# CBASS_MISC_PERI_CBASS_FW_45030000h register map
Vendor: Texas Instruments
Peripheral module from a debugger description file (folder AM275x).
Registers are 32-bit, read-write, reset 0x0 unless marked. A register's access mark holds for its fields unless they carry their own. Offsets are as the file gives them; lines under a group give offsets from that group; [hi:lo] are bit positions; {n}, {i} and the like mark numbered series; 'fields as' and 'values as' point back to an identical list; <NAME> marks a mode.

## cbass_fw (part 1 of 2)
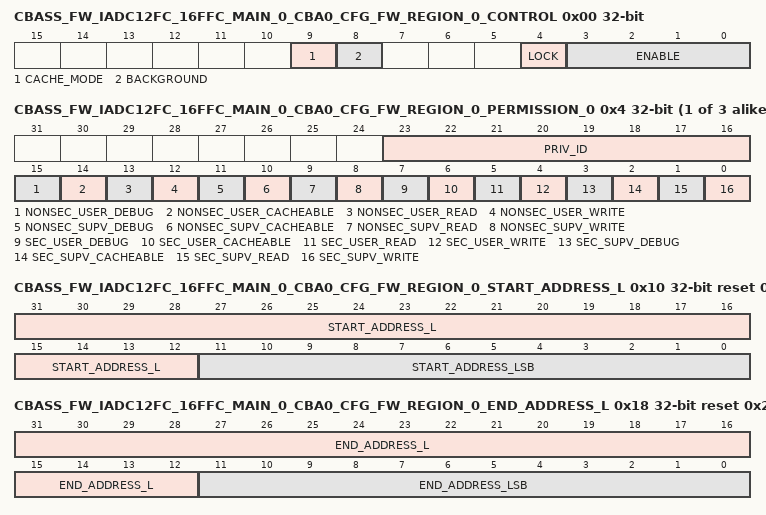
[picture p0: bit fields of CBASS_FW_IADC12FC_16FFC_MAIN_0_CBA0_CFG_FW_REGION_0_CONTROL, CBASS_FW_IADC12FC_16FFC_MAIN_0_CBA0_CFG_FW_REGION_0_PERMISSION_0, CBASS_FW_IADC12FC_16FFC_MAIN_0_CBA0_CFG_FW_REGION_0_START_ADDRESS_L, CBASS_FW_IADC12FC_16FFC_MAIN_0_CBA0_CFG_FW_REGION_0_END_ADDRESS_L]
0x00 CBASS_FW_IADC12FC_16FFC_MAIN_0_CBA0_CFG_FW_REGION_0_CONTROL access not given — The FW Region 0 Control Register defines the control fields for the target Iadc12fc_16ffc_main_0.cba0_cfg region 0 firewall.
  [9] CACHE_MODE rw — Cache mode for region. Set to 1 to check cache permissions. Set to 0 to ignore cache permissions. Reset Source: domain_default_rst_mod_g_rst_n
  [8] BACKGROUND rw — Background enable for region. There can be 1 backgroun region per FW and foreground regions can have overlapping addresses only with the background region. Reset Source: domain_default_rst_mod_g_rst_n
  [4] LOCK — Lock region. Once set region values cannot be modified. Reset Source: domain_default_rst_mod_g_rst_n (access R/W1TS)
  [3:0] ENABLE rw — Enable region. A value of 0xA enables, others disable. Reset Source: domain_default_rst_mod_g_rst_n
{0x4+4i} CBASS_FW_IADC12FC_16FFC_MAIN_0_CBA0_CFG_FW_REGION_0_PERMISSION_{i} (i=0..2) — The FW Region 0 Permission {i} Register defines the permissions for the target Iadc12fc_16ffc_main_0.cba0_cfg region 0 firewall.
  [23:16] PRIV_ID — Allowed privid. Reset Source: domain_default_rst_mod_g_rst_n
  [15] NONSEC_USER_DEBUG — Non-secure user debug allowed. Reset Source: domain_default_rst_mod_g_rst_n
  [14] NONSEC_USER_CACHEABLE — Non-secure user cacheable allowed. Reset Source: domain_default_rst_mod_g_rst_n
  [13] NONSEC_USER_READ — Non-secure user read allowed. Reset Source: domain_default_rst_mod_g_rst_n
  [12] NONSEC_USER_WRITE — Non-secure user write allowed. Reset Source: domain_default_rst_mod_g_rst_n
  [11] NONSEC_SUPV_DEBUG — Non-secure supervisor debug allowed. Reset Source: domain_default_rst_mod_g_rst_n
  [10] NONSEC_SUPV_CACHEABLE — Non-secure supervisor cacheable allowed. Reset Source: domain_default_rst_mod_g_rst_n
  [9] NONSEC_SUPV_READ — Non-secure supervisor read allowed. Reset Source: domain_default_rst_mod_g_rst_n
  [8] NONSEC_SUPV_WRITE — Non-secure supervisor write allowed. Reset Source: domain_default_rst_mod_g_rst_n
  [7] SEC_USER_DEBUG — Secure user debug allowed. Reset Source: domain_default_rst_mod_g_rst_n
  [6] SEC_USER_CACHEABLE — Secure user cacheable allowed. Reset Source: domain_default_rst_mod_g_rst_n
  [5] SEC_USER_READ — Secure user read allowed. Reset Source: domain_default_rst_mod_g_rst_n
  [4] SEC_USER_WRITE — Secure user write allowed. Reset Source: domain_default_rst_mod_g_rst_n
  [3] SEC_SUPV_DEBUG — Secure supervisor debug allowed. Reset Source: domain_default_rst_mod_g_rst_n
  [2] SEC_SUPV_CACHEABLE — Secure supervisor cacheable allowed. Reset Source: domain_default_rst_mod_g_rst_n
  [1] SEC_SUPV_READ — Secure supervisor read allowed. Reset Source: domain_default_rst_mod_g_rst_n
  [0] SEC_SUPV_WRITE — Secure supervisor write allowed. Reset Source: domain_default_rst_mod_g_rst_n
0x10 CBASS_FW_IADC12FC_16FFC_MAIN_0_CBA0_CFG_FW_REGION_0_START_ADDRESS_L access per field reset 0x20600000 — The FW Region 0 Start Address Low Register defines the start address bits 31 to 0 for the target Iadc12fc_16ffc_main_0.cba0_cfg region 0 firewall.
  [31:12] START_ADDRESS_L rw — Start address bits 31 to 12. Lowest 12 bits are forced to 0 as address must be 4KB aligned. Reset Source: domain_default_rst_mod_g_rst_n
  [11:0] START_ADDRESS_LSB ro — Start address bits 11 to 0 are forced to 0 as address must be 4KB aligned. Reset Source: domain_default_rst_mod_g_rst_n
0x14 CBASS_FW_IADC12FC_16FFC_MAIN_0_CBA0_CFG_FW_REGION_0_START_ADDRESS_H — The FW Region 0 Start Address High Register defines the start address bits 47 to 32 for the target Iadc12fc_16ffc_main_0.cba0_cfg region 0 firewall.
  [15:0] START_ADDRESS_H — Start address bits 47 to 32. Reset Source: domain_default_rst_mod_g_rst_n
0x18 CBASS_FW_IADC12FC_16FFC_MAIN_0_CBA0_CFG_FW_REGION_0_END_ADDRESS_L access per field reset 0x20600FFF — The FW Region 0 End Address Low Register defines the end address bits 31 to 0 to include for the target Iadc12fc_16ffc_main_0.cba0_cfg region 0 firewall.
  [31:12] END_ADDRESS_L rw — End address bits 31 to 12 to include in the match. Lowest 12 bits are forced to 1s as address must be 4KB aligned. Reset Source: domain_default_rst_mod_g_rst_n
  [11:0] END_ADDRESS_LSB ro — End address bits 11 to 0 are forced to 1s as address must be 4KB aligned minus 1. Reset Source: domain_default_rst_mod_g_rst_n
0x1C CBASS_FW_IADC12FC_16FFC_MAIN_0_CBA0_CFG_FW_REGION_0_END_ADDRESS_H — The FW Region 0 End Address High Register defines the end address bits 47 to 32 to include for the target Iadc12fc_16ffc_main_0.cba0_cfg region 0 firewall.
  [15:0] END_ADDRESS_H — End address bits 47 to 32 to include in the match. Reset Source: domain_default_rst_mod_g_rst_n
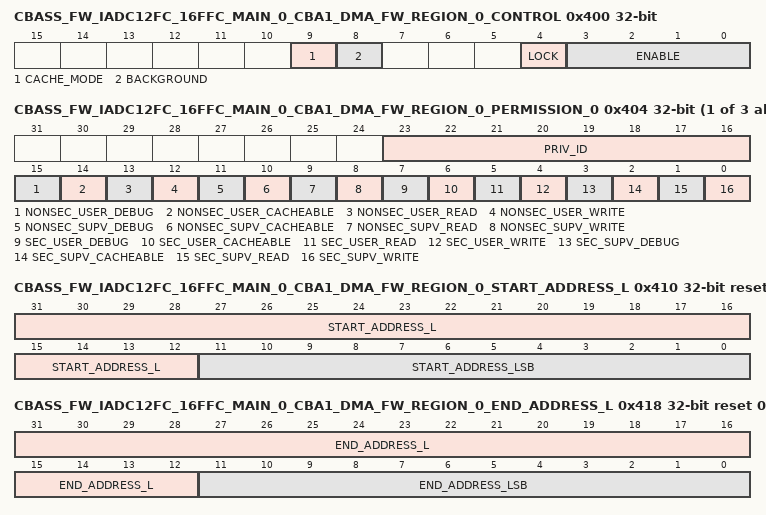
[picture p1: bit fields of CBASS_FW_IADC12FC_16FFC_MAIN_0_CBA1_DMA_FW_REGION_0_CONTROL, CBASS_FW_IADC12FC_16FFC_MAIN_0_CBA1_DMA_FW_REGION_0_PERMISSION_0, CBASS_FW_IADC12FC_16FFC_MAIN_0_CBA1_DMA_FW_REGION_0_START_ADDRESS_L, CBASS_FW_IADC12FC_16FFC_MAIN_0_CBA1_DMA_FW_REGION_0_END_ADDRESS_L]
0x400 CBASS_FW_IADC12FC_16FFC_MAIN_0_CBA1_DMA_FW_REGION_0_CONTROL access not given — The FW Region 0 Control Register defines the control fields for the target Iadc12fc_16ffc_main_0.cba1_dma region 0 firewall.
  fields as CBASS_FW_IADC12FC_16FFC_MAIN_0_CBA0_CFG_FW_REGION_0_CONTROL
{0x404+4i} CBASS_FW_IADC12FC_16FFC_MAIN_0_CBA1_DMA_FW_REGION_0_PERMISSION_{i} (i=0..2) — The FW Region 0 Permission {i} Register defines the permissions for the target Iadc12fc_16ffc_main_0.cba1_dma region 0 firewall.
  fields as CBASS_FW_IADC12FC_16FFC_MAIN_0_CBA0_CFG_FW_REGION_0_PERMISSION_0
0x410 CBASS_FW_IADC12FC_16FFC_MAIN_0_CBA1_DMA_FW_REGION_0_START_ADDRESS_L access per field reset 0x20608000 — The FW Region 0 Start Address Low Register defines the start address bits 31 to 0 for the target Iadc12fc_16ffc_main_0.cba1_dma region 0 firewall.
  fields as CBASS_FW_IADC12FC_16FFC_MAIN_0_CBA0_CFG_FW_REGION_0_START_ADDRESS_L
0x414 CBASS_FW_IADC12FC_16FFC_MAIN_0_CBA1_DMA_FW_REGION_0_START_ADDRESS_H — The FW Region 0 Start Address High Register defines the start address bits 47 to 32 for the target Iadc12fc_16ffc_main_0.cba1_dma region 0 firewall.
  fields as CBASS_FW_IADC12FC_16FFC_MAIN_0_CBA0_CFG_FW_REGION_0_START_ADDRESS_H
0x418 CBASS_FW_IADC12FC_16FFC_MAIN_0_CBA1_DMA_FW_REGION_0_END_ADDRESS_L access per field reset 0x20608FFF — The FW Region 0 End Address Low Register defines the end address bits 31 to 0 to include for the target Iadc12fc_16ffc_main_0.cba1_dma region 0 firewall.
  fields as CBASS_FW_IADC12FC_16FFC_MAIN_0_CBA0_CFG_FW_REGION_0_END_ADDRESS_L
0x41C CBASS_FW_IADC12FC_16FFC_MAIN_0_CBA1_DMA_FW_REGION_0_END_ADDRESS_H — The FW Region 0 End Address High Register defines the end address bits 47 to 32 to include for the target Iadc12fc_16ffc_main_0.cba1_dma region 0 firewall.
  fields as CBASS_FW_IADC12FC_16FFC_MAIN_0_CBA0_CFG_FW_REGION_0_END_ADDRESS_H
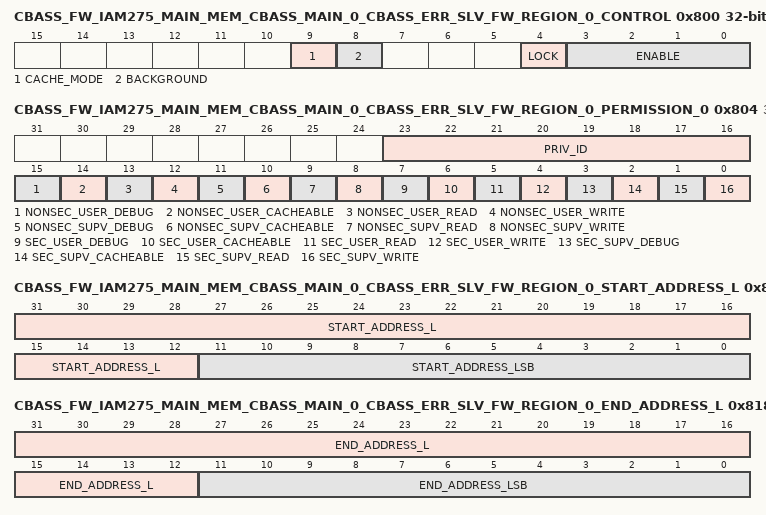
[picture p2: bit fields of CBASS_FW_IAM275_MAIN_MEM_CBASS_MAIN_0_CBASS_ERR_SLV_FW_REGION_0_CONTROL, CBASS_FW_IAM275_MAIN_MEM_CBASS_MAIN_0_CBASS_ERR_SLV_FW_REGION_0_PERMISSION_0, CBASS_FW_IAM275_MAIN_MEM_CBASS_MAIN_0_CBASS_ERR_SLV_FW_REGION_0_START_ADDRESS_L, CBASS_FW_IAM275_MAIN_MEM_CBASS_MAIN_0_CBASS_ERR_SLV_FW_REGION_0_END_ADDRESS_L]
0x800 CBASS_FW_IAM275_MAIN_MEM_CBASS_MAIN_0_CBASS_ERR_SLV_FW_REGION_0_CONTROL access not given — The FW Region 0 Control Register defines the control fields for the target Iam275_main_mem_cbass_main_0.cbass_err_slv region 0 firewall.
  fields as CBASS_FW_IADC12FC_16FFC_MAIN_0_CBA0_CFG_FW_REGION_0_CONTROL
{0x804+4i} CBASS_FW_IAM275_MAIN_MEM_CBASS_MAIN_0_CBASS_ERR_SLV_FW_REGION_0_PERMISSION_{i} (i=0..2) — The FW Region 0 Permission {i} Register defines the permissions for the target Iam275_main_mem_cbass_main_0.cbass_err_slv region 0 firewall.
  fields as CBASS_FW_IADC12FC_16FFC_MAIN_0_CBA0_CFG_FW_REGION_0_PERMISSION_0
0x810 CBASS_FW_IAM275_MAIN_MEM_CBASS_MAIN_0_CBASS_ERR_SLV_FW_REGION_0_START_ADDRESS_L access per field reset 0x20200000 — The FW Region 0 Start Address Low Register defines the start address bits 31 to 0 for the target Iam275_main_mem_cbass_main_0.cbass_err_slv region 0 firewall.
  fields as CBASS_FW_IADC12FC_16FFC_MAIN_0_CBA0_CFG_FW_REGION_0_START_ADDRESS_L
0x814 CBASS_FW_IAM275_MAIN_MEM_CBASS_MAIN_0_CBASS_ERR_SLV_FW_REGION_0_START_ADDRESS_H — The FW Region 0 Start Address High Register defines the start address bits 47 to 32 for the target Iam275_main_mem_cbass_main_0.cbass_err_slv region 0 firewall.
  fields as CBASS_FW_IADC12FC_16FFC_MAIN_0_CBA0_CFG_FW_REGION_0_START_ADDRESS_H
0x818 CBASS_FW_IAM275_MAIN_MEM_CBASS_MAIN_0_CBASS_ERR_SLV_FW_REGION_0_END_ADDRESS_L access per field reset 0x20200FFF — The FW Region 0 End Address Low Register defines the end address bits 31 to 0 to include for the target Iam275_main_mem_cbass_main_0.cbass_err_slv region 0 firewall.
  fields as CBASS_FW_IADC12FC_16FFC_MAIN_0_CBA0_CFG_FW_REGION_0_END_ADDRESS_L
0x81C CBASS_FW_IAM275_MAIN_MEM_CBASS_MAIN_0_CBASS_ERR_SLV_FW_REGION_0_END_ADDRESS_H — The FW Region 0 End Address High Register defines the end address bits 47 to 32 to include for the target Iam275_main_mem_cbass_main_0.cbass_err_slv region 0 firewall.
  fields as CBASS_FW_IADC12FC_16FFC_MAIN_0_CBA0_CFG_FW_REGION_0_END_ADDRESS_H
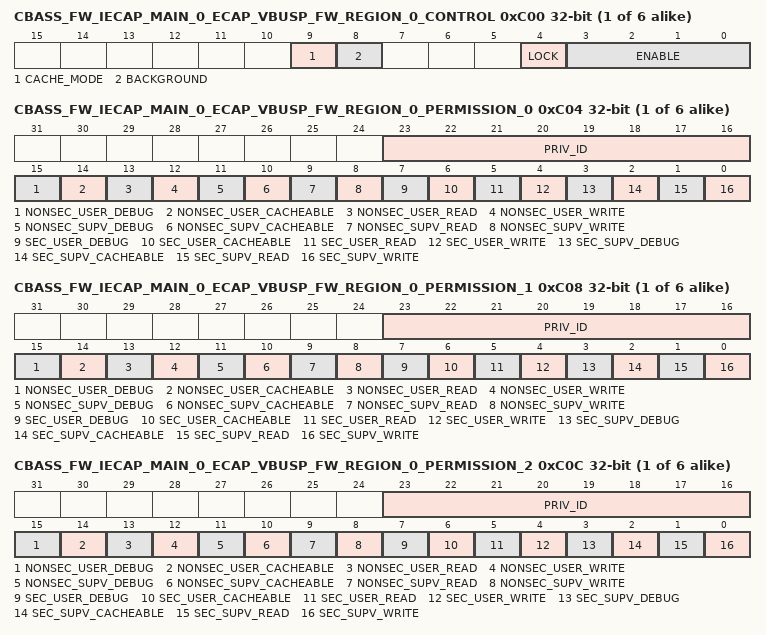
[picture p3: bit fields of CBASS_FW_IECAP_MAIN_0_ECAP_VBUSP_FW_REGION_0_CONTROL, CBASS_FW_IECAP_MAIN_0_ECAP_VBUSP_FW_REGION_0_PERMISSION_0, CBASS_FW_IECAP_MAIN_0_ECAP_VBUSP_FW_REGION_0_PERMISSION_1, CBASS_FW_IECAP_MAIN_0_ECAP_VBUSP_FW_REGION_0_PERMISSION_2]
{0xC00+0x400*i} CBASS_FW_IECAP_MAIN_{i}_ECAP_VBUSP_FW_REGION_0_CONTROL access not given (i=0..5) — The FW Region 0 Control Register defines the control fields for the target Iecap_main_{i}.ecap_vbusp region 0 firewall.
  fields as CBASS_FW_IADC12FC_16FFC_MAIN_0_CBA0_CFG_FW_REGION_0_CONTROL
{0xC04+0x400*i} CBASS_FW_IECAP_MAIN_{i}_ECAP_VBUSP_FW_REGION_0_PERMISSION_0 (i=0..5) — The FW Region 0 Permission 0 Register defines the permissions for the target Iecap_main_{i}.ecap_vbusp region 0 firewall.
  fields as CBASS_FW_IADC12FC_16FFC_MAIN_0_CBA0_CFG_FW_REGION_0_PERMISSION_0
{0xC08+0x400*i} CBASS_FW_IECAP_MAIN_{i}_ECAP_VBUSP_FW_REGION_0_PERMISSION_1 (i=0..5) — The FW Region 0 Permission 1 Register defines the permissions for the target Iecap_main_{i}.ecap_vbusp region 0 firewall.
  fields as CBASS_FW_IADC12FC_16FFC_MAIN_0_CBA0_CFG_FW_REGION_0_PERMISSION_0
{0xC0C+0x400*i} CBASS_FW_IECAP_MAIN_{i}_ECAP_VBUSP_FW_REGION_0_PERMISSION_2 (i=0..5) — The FW Region 0 Permission 2 Register defines the permissions for the target Iecap_main_{i}.ecap_vbusp region 0 firewall.
  fields as CBASS_FW_IADC12FC_16FFC_MAIN_0_CBA0_CFG_FW_REGION_0_PERMISSION_0
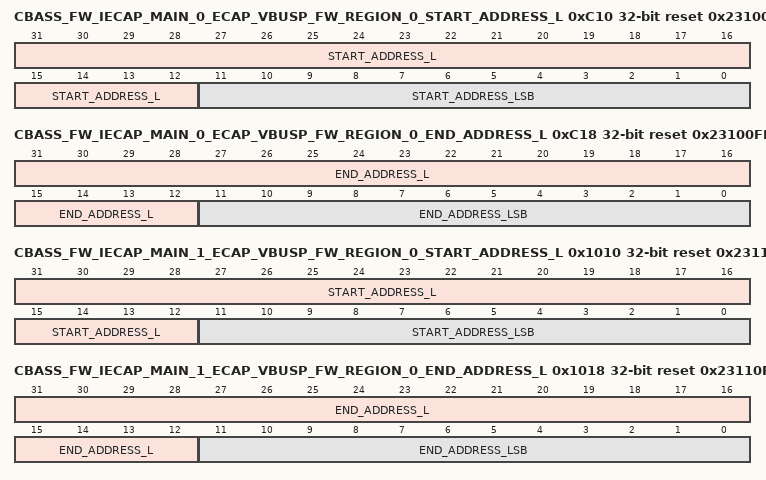
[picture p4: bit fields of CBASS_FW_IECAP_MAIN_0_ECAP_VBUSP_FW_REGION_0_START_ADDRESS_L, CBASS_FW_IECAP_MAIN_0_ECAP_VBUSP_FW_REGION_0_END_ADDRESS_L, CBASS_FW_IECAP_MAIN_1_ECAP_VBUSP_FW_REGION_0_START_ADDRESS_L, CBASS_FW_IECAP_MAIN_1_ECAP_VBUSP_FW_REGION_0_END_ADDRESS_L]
0xC10 CBASS_FW_IECAP_MAIN_0_ECAP_VBUSP_FW_REGION_0_START_ADDRESS_L access per field reset 0x23100000 — The FW Region 0 Start Address Low Register defines the start address bits 31 to 0 for the target Iecap_main_0.ecap_vbusp region 0 firewall.
  fields as CBASS_FW_IADC12FC_16FFC_MAIN_0_CBA0_CFG_FW_REGION_0_START_ADDRESS_L
{0xC14+0x400*i} CBASS_FW_IECAP_MAIN_{i}_ECAP_VBUSP_FW_REGION_0_START_ADDRESS_H (i=0..5) — The FW Region 0 Start Address High Register defines the start address bits 47 to 32 for the target Iecap_main_{i}.ecap_vbusp region 0 firewall.
  fields as CBASS_FW_IADC12FC_16FFC_MAIN_0_CBA0_CFG_FW_REGION_0_START_ADDRESS_H
0xC18 CBASS_FW_IECAP_MAIN_0_ECAP_VBUSP_FW_REGION_0_END_ADDRESS_L access per field reset 0x23100FFF — The FW Region 0 End Address Low Register defines the end address bits 31 to 0 to include for the target Iecap_main_0.ecap_vbusp region 0 firewall.
  fields as CBASS_FW_IADC12FC_16FFC_MAIN_0_CBA0_CFG_FW_REGION_0_END_ADDRESS_L
{0xC1C+0x400*i} CBASS_FW_IECAP_MAIN_{i}_ECAP_VBUSP_FW_REGION_0_END_ADDRESS_H (i=0..5) — The FW Region 0 End Address High Register defines the end address bits 47 to 32 to include for the target Iecap_main_{i}.ecap_vbusp region 0 firewall.
  fields as CBASS_FW_IADC12FC_16FFC_MAIN_0_CBA0_CFG_FW_REGION_0_END_ADDRESS_H
0x1010 CBASS_FW_IECAP_MAIN_1_ECAP_VBUSP_FW_REGION_0_START_ADDRESS_L access per field reset 0x23110000 — The FW Region 0 Start Address Low Register defines the start address bits 31 to 0 for the target Iecap_main_1.ecap_vbusp region 0 firewall.
  fields as CBASS_FW_IADC12FC_16FFC_MAIN_0_CBA0_CFG_FW_REGION_0_START_ADDRESS_L
0x1018 CBASS_FW_IECAP_MAIN_1_ECAP_VBUSP_FW_REGION_0_END_ADDRESS_L access per field reset 0x23110FFF — The FW Region 0 End Address Low Register defines the end address bits 31 to 0 to include for the target Iecap_main_1.ecap_vbusp region 0 firewall.
  fields as CBASS_FW_IADC12FC_16FFC_MAIN_0_CBA0_CFG_FW_REGION_0_END_ADDRESS_L
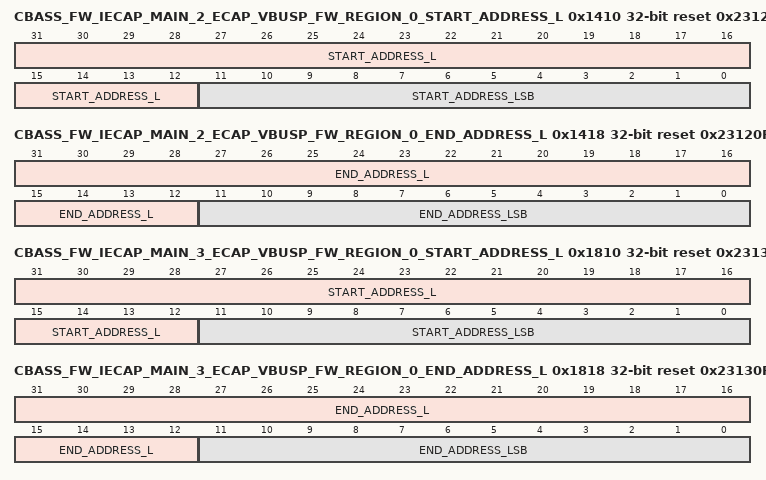
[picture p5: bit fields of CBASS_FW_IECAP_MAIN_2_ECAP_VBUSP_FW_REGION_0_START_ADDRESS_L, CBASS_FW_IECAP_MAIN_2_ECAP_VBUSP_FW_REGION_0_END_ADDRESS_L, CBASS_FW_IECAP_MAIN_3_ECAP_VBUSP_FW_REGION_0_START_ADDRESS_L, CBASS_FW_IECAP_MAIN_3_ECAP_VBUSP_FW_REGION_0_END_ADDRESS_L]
0x1410 CBASS_FW_IECAP_MAIN_2_ECAP_VBUSP_FW_REGION_0_START_ADDRESS_L access per field reset 0x23120000 — The FW Region 0 Start Address Low Register defines the start address bits 31 to 0 for the target Iecap_main_2.ecap_vbusp region 0 firewall.
  fields as CBASS_FW_IADC12FC_16FFC_MAIN_0_CBA0_CFG_FW_REGION_0_START_ADDRESS_L
0x1418 CBASS_FW_IECAP_MAIN_2_ECAP_VBUSP_FW_REGION_0_END_ADDRESS_L access per field reset 0x23120FFF — The FW Region 0 End Address Low Register defines the end address bits 31 to 0 to include for the target Iecap_main_2.ecap_vbusp region 0 firewall.
  fields as CBASS_FW_IADC12FC_16FFC_MAIN_0_CBA0_CFG_FW_REGION_0_END_ADDRESS_L
0x1810 CBASS_FW_IECAP_MAIN_3_ECAP_VBUSP_FW_REGION_0_START_ADDRESS_L access per field reset 0x23130000 — The FW Region 0 Start Address Low Register defines the start address bits 31 to 0 for the target Iecap_main_3.ecap_vbusp region 0 firewall.
  fields as CBASS_FW_IADC12FC_16FFC_MAIN_0_CBA0_CFG_FW_REGION_0_START_ADDRESS_L
0x1818 CBASS_FW_IECAP_MAIN_3_ECAP_VBUSP_FW_REGION_0_END_ADDRESS_L access per field reset 0x23130FFF — The FW Region 0 End Address Low Register defines the end address bits 31 to 0 to include for the target Iecap_main_3.ecap_vbusp region 0 firewall.
  fields as CBASS_FW_IADC12FC_16FFC_MAIN_0_CBA0_CFG_FW_REGION_0_END_ADDRESS_L
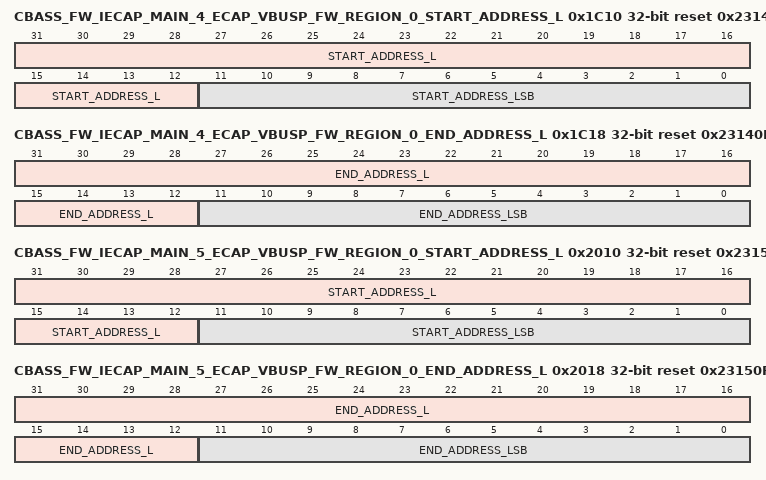
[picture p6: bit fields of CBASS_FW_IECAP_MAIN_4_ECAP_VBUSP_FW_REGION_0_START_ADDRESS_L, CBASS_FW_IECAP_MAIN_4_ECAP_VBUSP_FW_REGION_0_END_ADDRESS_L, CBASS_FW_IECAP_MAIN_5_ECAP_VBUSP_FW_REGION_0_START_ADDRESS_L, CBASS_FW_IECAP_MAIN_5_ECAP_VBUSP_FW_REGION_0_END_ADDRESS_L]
0x1C10 CBASS_FW_IECAP_MAIN_4_ECAP_VBUSP_FW_REGION_0_START_ADDRESS_L access per field reset 0x23140000 — The FW Region 0 Start Address Low Register defines the start address bits 31 to 0 for the target Iecap_main_4.ecap_vbusp region 0 firewall.
  fields as CBASS_FW_IADC12FC_16FFC_MAIN_0_CBA0_CFG_FW_REGION_0_START_ADDRESS_L
0x1C18 CBASS_FW_IECAP_MAIN_4_ECAP_VBUSP_FW_REGION_0_END_ADDRESS_L access per field reset 0x23140FFF — The FW Region 0 End Address Low Register defines the end address bits 31 to 0 to include for the target Iecap_main_4.ecap_vbusp region 0 firewall.
  fields as CBASS_FW_IADC12FC_16FFC_MAIN_0_CBA0_CFG_FW_REGION_0_END_ADDRESS_L
0x2010 CBASS_FW_IECAP_MAIN_5_ECAP_VBUSP_FW_REGION_0_START_ADDRESS_L access per field reset 0x23150000 — The FW Region 0 Start Address Low Register defines the start address bits 31 to 0 for the target Iecap_main_5.ecap_vbusp region 0 firewall.
  fields as CBASS_FW_IADC12FC_16FFC_MAIN_0_CBA0_CFG_FW_REGION_0_START_ADDRESS_L
0x2018 CBASS_FW_IECAP_MAIN_5_ECAP_VBUSP_FW_REGION_0_END_ADDRESS_L access per field reset 0x23150FFF — The FW Region 0 End Address Low Register defines the end address bits 31 to 0 to include for the target Iecap_main_5.ecap_vbusp region 0 firewall.
  fields as CBASS_FW_IADC12FC_16FFC_MAIN_0_CBA0_CFG_FW_REGION_0_END_ADDRESS_L
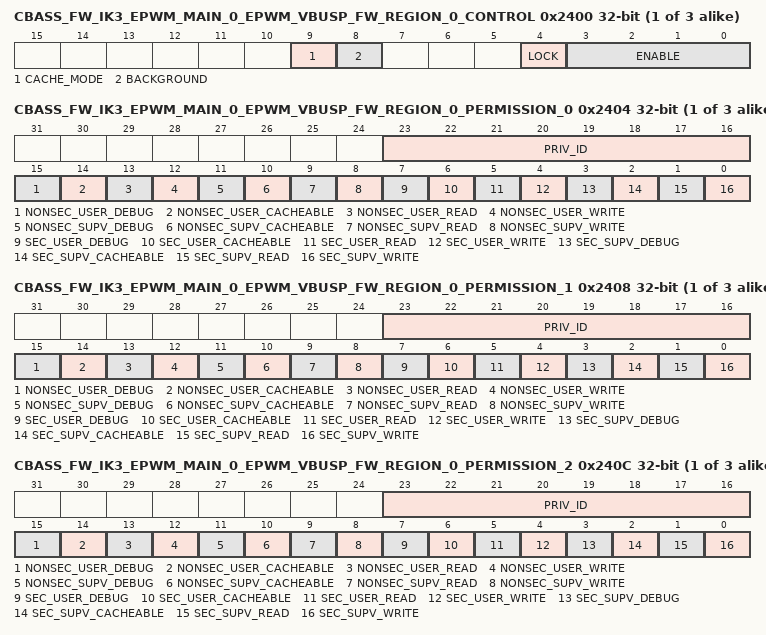
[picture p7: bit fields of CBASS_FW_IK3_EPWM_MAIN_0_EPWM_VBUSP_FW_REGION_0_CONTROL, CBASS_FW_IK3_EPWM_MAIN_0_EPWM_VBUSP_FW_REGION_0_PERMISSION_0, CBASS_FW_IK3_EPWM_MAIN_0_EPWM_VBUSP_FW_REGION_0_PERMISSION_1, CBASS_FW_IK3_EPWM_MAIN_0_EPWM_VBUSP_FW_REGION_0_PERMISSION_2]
{0x2400+0x400*i} CBASS_FW_IK3_EPWM_MAIN_{i}_EPWM_VBUSP_FW_REGION_0_CONTROL access not given (i=0..2) — The FW Region 0 Control Register defines the control fields for the target Ik3_epwm_main_{i}.epwm_vbusp region 0 firewall.
  fields as CBASS_FW_IADC12FC_16FFC_MAIN_0_CBA0_CFG_FW_REGION_0_CONTROL
{0x2404+0x400*i} CBASS_FW_IK3_EPWM_MAIN_{i}_EPWM_VBUSP_FW_REGION_0_PERMISSION_0 (i=0..2) — The FW Region 0 Permission 0 Register defines the permissions for the target Ik3_epwm_main_{i}.epwm_vbusp region 0 firewall.
  fields as CBASS_FW_IADC12FC_16FFC_MAIN_0_CBA0_CFG_FW_REGION_0_PERMISSION_0
{0x2408+0x400*i} CBASS_FW_IK3_EPWM_MAIN_{i}_EPWM_VBUSP_FW_REGION_0_PERMISSION_1 (i=0..2) — The FW Region 0 Permission 1 Register defines the permissions for the target Ik3_epwm_main_{i}.epwm_vbusp region 0 firewall.
  fields as CBASS_FW_IADC12FC_16FFC_MAIN_0_CBA0_CFG_FW_REGION_0_PERMISSION_0
{0x240C+0x400*i} CBASS_FW_IK3_EPWM_MAIN_{i}_EPWM_VBUSP_FW_REGION_0_PERMISSION_2 (i=0..2) — The FW Region 0 Permission 2 Register defines the permissions for the target Ik3_epwm_main_{i}.epwm_vbusp region 0 firewall.
  fields as CBASS_FW_IADC12FC_16FFC_MAIN_0_CBA0_CFG_FW_REGION_0_PERMISSION_0
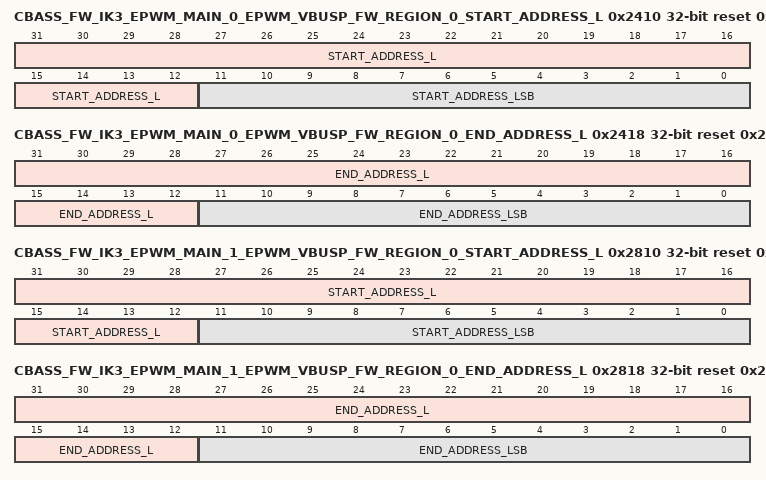
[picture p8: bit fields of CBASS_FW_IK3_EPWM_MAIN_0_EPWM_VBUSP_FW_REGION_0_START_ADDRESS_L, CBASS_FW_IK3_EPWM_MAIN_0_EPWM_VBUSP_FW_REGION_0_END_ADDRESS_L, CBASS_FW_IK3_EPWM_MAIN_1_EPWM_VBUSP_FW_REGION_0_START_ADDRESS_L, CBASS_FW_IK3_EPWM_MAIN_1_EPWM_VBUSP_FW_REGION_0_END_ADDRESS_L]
0x2410 CBASS_FW_IK3_EPWM_MAIN_0_EPWM_VBUSP_FW_REGION_0_START_ADDRESS_L access per field reset 0x23000000 — The FW Region 0 Start Address Low Register defines the start address bits 31 to 0 for the target Ik3_epwm_main_0.epwm_vbusp region 0 firewall.
  fields as CBASS_FW_IADC12FC_16FFC_MAIN_0_CBA0_CFG_FW_REGION_0_START_ADDRESS_L
{0x2414+0x400*i} CBASS_FW_IK3_EPWM_MAIN_{i}_EPWM_VBUSP_FW_REGION_0_START_ADDRESS_H (i=0..2) — The FW Region 0 Start Address High Register defines the start address bits 47 to 32 for the target Ik3_epwm_main_{i}.epwm_vbusp region 0 firewall.
  fields as CBASS_FW_IADC12FC_16FFC_MAIN_0_CBA0_CFG_FW_REGION_0_START_ADDRESS_H
0x2418 CBASS_FW_IK3_EPWM_MAIN_0_EPWM_VBUSP_FW_REGION_0_END_ADDRESS_L access per field reset 0x23000FFF — The FW Region 0 End Address Low Register defines the end address bits 31 to 0 to include for the target Ik3_epwm_main_0.epwm_vbusp region 0 firewall.
  fields as CBASS_FW_IADC12FC_16FFC_MAIN_0_CBA0_CFG_FW_REGION_0_END_ADDRESS_L
{0x241C+0x400*i} CBASS_FW_IK3_EPWM_MAIN_{i}_EPWM_VBUSP_FW_REGION_0_END_ADDRESS_H (i=0..2) — The FW Region 0 End Address High Register defines the end address bits 47 to 32 to include for the target Ik3_epwm_main_{i}.epwm_vbusp region 0 firewall.
  fields as CBASS_FW_IADC12FC_16FFC_MAIN_0_CBA0_CFG_FW_REGION_0_END_ADDRESS_H
0x2810 CBASS_FW_IK3_EPWM_MAIN_1_EPWM_VBUSP_FW_REGION_0_START_ADDRESS_L access per field reset 0x23010000 — The FW Region 0 Start Address Low Register defines the start address bits 31 to 0 for the target Ik3_epwm_main_1.epwm_vbusp region 0 firewall.
  fields as CBASS_FW_IADC12FC_16FFC_MAIN_0_CBA0_CFG_FW_REGION_0_START_ADDRESS_L
0x2818 CBASS_FW_IK3_EPWM_MAIN_1_EPWM_VBUSP_FW_REGION_0_END_ADDRESS_L access per field reset 0x23010FFF — The FW Region 0 End Address Low Register defines the end address bits 31 to 0 to include for the target Ik3_epwm_main_1.epwm_vbusp region 0 firewall.
  fields as CBASS_FW_IADC12FC_16FFC_MAIN_0_CBA0_CFG_FW_REGION_0_END_ADDRESS_L
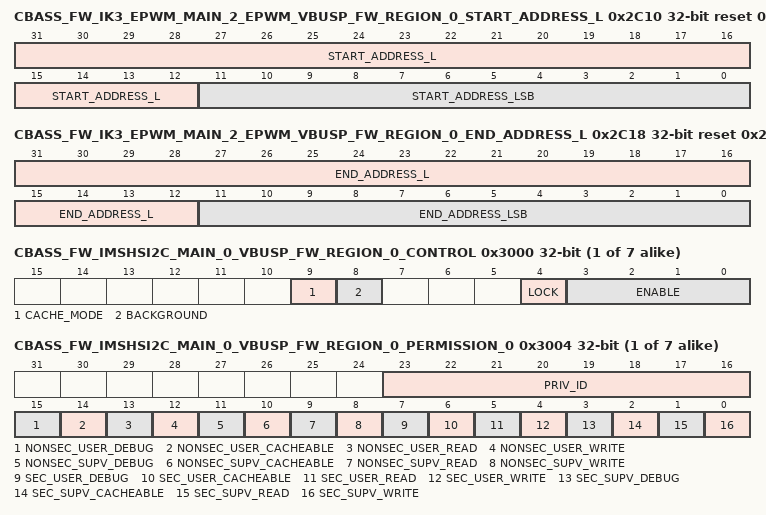
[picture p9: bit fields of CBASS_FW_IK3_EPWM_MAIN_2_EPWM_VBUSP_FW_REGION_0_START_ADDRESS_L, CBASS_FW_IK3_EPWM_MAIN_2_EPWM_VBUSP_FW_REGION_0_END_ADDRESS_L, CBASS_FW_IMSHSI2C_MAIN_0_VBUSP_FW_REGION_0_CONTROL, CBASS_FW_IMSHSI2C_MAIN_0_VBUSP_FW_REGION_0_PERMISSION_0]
0x2C10 CBASS_FW_IK3_EPWM_MAIN_2_EPWM_VBUSP_FW_REGION_0_START_ADDRESS_L access per field reset 0x23020000 — The FW Region 0 Start Address Low Register defines the start address bits 31 to 0 for the target Ik3_epwm_main_2.epwm_vbusp region 0 firewall.
  fields as CBASS_FW_IADC12FC_16FFC_MAIN_0_CBA0_CFG_FW_REGION_0_START_ADDRESS_L
0x2C18 CBASS_FW_IK3_EPWM_MAIN_2_EPWM_VBUSP_FW_REGION_0_END_ADDRESS_L access per field reset 0x23020FFF — The FW Region 0 End Address Low Register defines the end address bits 31 to 0 to include for the target Ik3_epwm_main_2.epwm_vbusp region 0 firewall.
  fields as CBASS_FW_IADC12FC_16FFC_MAIN_0_CBA0_CFG_FW_REGION_0_END_ADDRESS_L
{0x3000+0x400*i} CBASS_FW_IMSHSI2C_MAIN_{i}_VBUSP_FW_REGION_0_CONTROL access not given (i=0..6) — The FW Region 0 Control Register defines the control fields for the target Imshsi2c_main_{i}.vbusp region 0 firewall.
  fields as CBASS_FW_IADC12FC_16FFC_MAIN_0_CBA0_CFG_FW_REGION_0_CONTROL
{0x3004+0x400*i} CBASS_FW_IMSHSI2C_MAIN_{i}_VBUSP_FW_REGION_0_PERMISSION_0 (i=0..6) — The FW Region 0 Permission 0 Register defines the permissions for the target Imshsi2c_main_{i}.vbusp region 0 firewall.
  fields as CBASS_FW_IADC12FC_16FFC_MAIN_0_CBA0_CFG_FW_REGION_0_PERMISSION_0
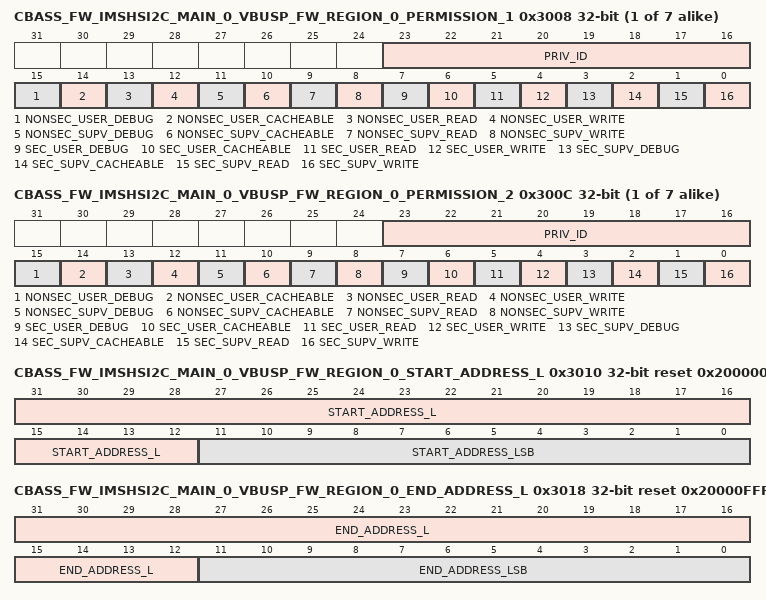
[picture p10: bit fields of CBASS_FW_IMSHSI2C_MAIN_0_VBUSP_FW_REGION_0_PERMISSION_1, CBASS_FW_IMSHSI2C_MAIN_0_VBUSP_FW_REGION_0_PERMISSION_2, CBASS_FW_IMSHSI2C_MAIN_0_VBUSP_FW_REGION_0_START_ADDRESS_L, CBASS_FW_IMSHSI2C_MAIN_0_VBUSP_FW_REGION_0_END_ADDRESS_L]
{0x3008+0x400*i} CBASS_FW_IMSHSI2C_MAIN_{i}_VBUSP_FW_REGION_0_PERMISSION_1 (i=0..6) — The FW Region 0 Permission 1 Register defines the permissions for the target Imshsi2c_main_{i}.vbusp region 0 firewall.
  fields as CBASS_FW_IADC12FC_16FFC_MAIN_0_CBA0_CFG_FW_REGION_0_PERMISSION_0
{0x300C+0x400*i} CBASS_FW_IMSHSI2C_MAIN_{i}_VBUSP_FW_REGION_0_PERMISSION_2 (i=0..6) — The FW Region 0 Permission 2 Register defines the permissions for the target Imshsi2c_main_{i}.vbusp region 0 firewall.
  fields as CBASS_FW_IADC12FC_16FFC_MAIN_0_CBA0_CFG_FW_REGION_0_PERMISSION_0
0x3010 CBASS_FW_IMSHSI2C_MAIN_0_VBUSP_FW_REGION_0_START_ADDRESS_L access per field reset 0x20000000 — The FW Region 0 Start Address Low Register defines the start address bits 31 to 0 for the target Imshsi2c_main_0.vbusp region 0 firewall.
  fields as CBASS_FW_IADC12FC_16FFC_MAIN_0_CBA0_CFG_FW_REGION_0_START_ADDRESS_L
{0x3014+0x400*i} CBASS_FW_IMSHSI2C_MAIN_{i}_VBUSP_FW_REGION_0_START_ADDRESS_H (i=0..6) — The FW Region 0 Start Address High Register defines the start address bits 47 to 32 for the target Imshsi2c_main_{i}.vbusp region 0 firewall.
  fields as CBASS_FW_IADC12FC_16FFC_MAIN_0_CBA0_CFG_FW_REGION_0_START_ADDRESS_H
0x3018 CBASS_FW_IMSHSI2C_MAIN_0_VBUSP_FW_REGION_0_END_ADDRESS_L access per field reset 0x20000FFF — The FW Region 0 End Address Low Register defines the end address bits 31 to 0 to include for the target Imshsi2c_main_0.vbusp region 0 firewall.
  fields as CBASS_FW_IADC12FC_16FFC_MAIN_0_CBA0_CFG_FW_REGION_0_END_ADDRESS_L
{0x301C+0x400*i} CBASS_FW_IMSHSI2C_MAIN_{i}_VBUSP_FW_REGION_0_END_ADDRESS_H (i=0..6) — The FW Region 0 End Address High Register defines the end address bits 47 to 32 to include for the target Imshsi2c_main_{i}.vbusp region 0 firewall.
  fields as CBASS_FW_IADC12FC_16FFC_MAIN_0_CBA0_CFG_FW_REGION_0_END_ADDRESS_H
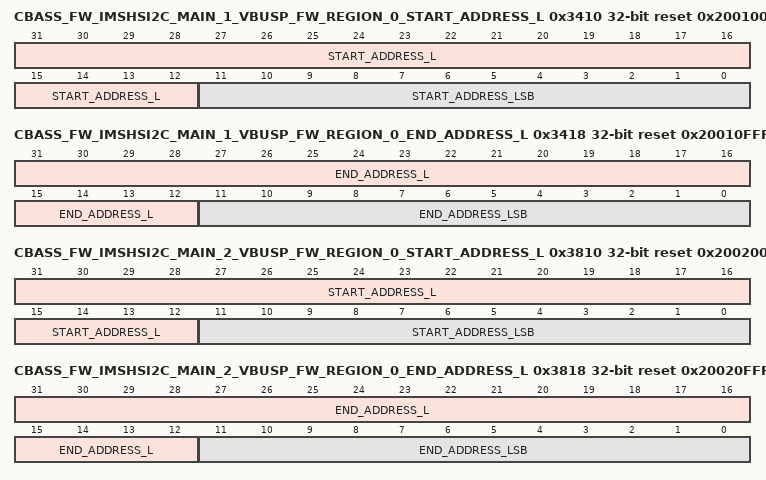
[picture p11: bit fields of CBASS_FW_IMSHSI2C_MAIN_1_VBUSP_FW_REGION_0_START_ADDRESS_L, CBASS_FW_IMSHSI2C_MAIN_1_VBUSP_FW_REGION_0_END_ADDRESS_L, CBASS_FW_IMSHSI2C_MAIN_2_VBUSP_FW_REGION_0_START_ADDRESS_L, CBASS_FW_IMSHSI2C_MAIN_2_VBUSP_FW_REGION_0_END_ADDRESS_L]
0x3410 CBASS_FW_IMSHSI2C_MAIN_1_VBUSP_FW_REGION_0_START_ADDRESS_L access per field reset 0x20010000 — The FW Region 0 Start Address Low Register defines the start address bits 31 to 0 for the target Imshsi2c_main_1.vbusp region 0 firewall.
  fields as CBASS_FW_IADC12FC_16FFC_MAIN_0_CBA0_CFG_FW_REGION_0_START_ADDRESS_L
0x3418 CBASS_FW_IMSHSI2C_MAIN_1_VBUSP_FW_REGION_0_END_ADDRESS_L access per field reset 0x20010FFF — The FW Region 0 End Address Low Register defines the end address bits 31 to 0 to include for the target Imshsi2c_main_1.vbusp region 0 firewall.
  fields as CBASS_FW_IADC12FC_16FFC_MAIN_0_CBA0_CFG_FW_REGION_0_END_ADDRESS_L
0x3810 CBASS_FW_IMSHSI2C_MAIN_2_VBUSP_FW_REGION_0_START_ADDRESS_L access per field reset 0x20020000 — The FW Region 0 Start Address Low Register defines the start address bits 31 to 0 for the target Imshsi2c_main_2.vbusp region 0 firewall.
  fields as CBASS_FW_IADC12FC_16FFC_MAIN_0_CBA0_CFG_FW_REGION_0_START_ADDRESS_L
0x3818 CBASS_FW_IMSHSI2C_MAIN_2_VBUSP_FW_REGION_0_END_ADDRESS_L access per field reset 0x20020FFF — The FW Region 0 End Address Low Register defines the end address bits 31 to 0 to include for the target Imshsi2c_main_2.vbusp region 0 firewall.
  fields as CBASS_FW_IADC12FC_16FFC_MAIN_0_CBA0_CFG_FW_REGION_0_END_ADDRESS_L
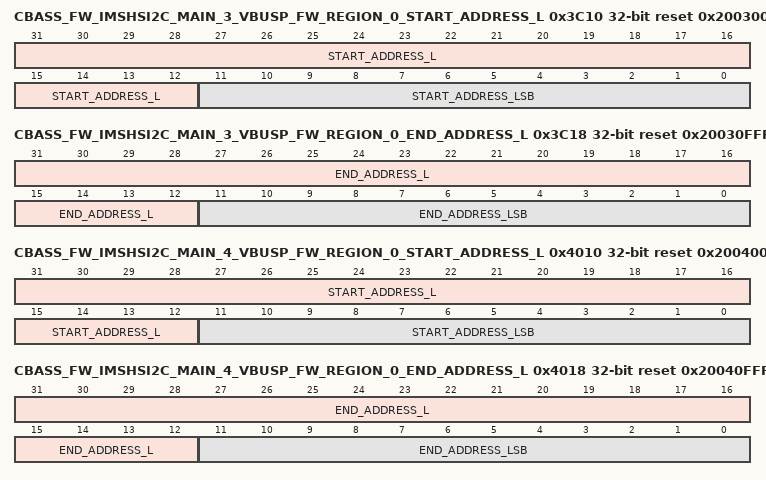
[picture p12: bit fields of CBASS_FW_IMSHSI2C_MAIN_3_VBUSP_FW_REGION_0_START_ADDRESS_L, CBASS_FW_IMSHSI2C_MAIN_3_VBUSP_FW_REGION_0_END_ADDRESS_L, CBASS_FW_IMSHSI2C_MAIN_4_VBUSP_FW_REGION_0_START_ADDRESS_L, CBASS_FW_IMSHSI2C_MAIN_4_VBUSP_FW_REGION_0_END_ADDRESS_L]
0x3C10 CBASS_FW_IMSHSI2C_MAIN_3_VBUSP_FW_REGION_0_START_ADDRESS_L access per field reset 0x20030000 — The FW Region 0 Start Address Low Register defines the start address bits 31 to 0 for the target Imshsi2c_main_3.vbusp region 0 firewall.
  fields as CBASS_FW_IADC12FC_16FFC_MAIN_0_CBA0_CFG_FW_REGION_0_START_ADDRESS_L
0x3C18 CBASS_FW_IMSHSI2C_MAIN_3_VBUSP_FW_REGION_0_END_ADDRESS_L access per field reset 0x20030FFF — The FW Region 0 End Address Low Register defines the end address bits 31 to 0 to include for the target Imshsi2c_main_3.vbusp region 0 firewall.
  fields as CBASS_FW_IADC12FC_16FFC_MAIN_0_CBA0_CFG_FW_REGION_0_END_ADDRESS_L
0x4010 CBASS_FW_IMSHSI2C_MAIN_4_VBUSP_FW_REGION_0_START_ADDRESS_L access per field reset 0x20040000 — The FW Region 0 Start Address Low Register defines the start address bits 31 to 0 for the target Imshsi2c_main_4.vbusp region 0 firewall.
  fields as CBASS_FW_IADC12FC_16FFC_MAIN_0_CBA0_CFG_FW_REGION_0_START_ADDRESS_L
0x4018 CBASS_FW_IMSHSI2C_MAIN_4_VBUSP_FW_REGION_0_END_ADDRESS_L access per field reset 0x20040FFF — The FW Region 0 End Address Low Register defines the end address bits 31 to 0 to include for the target Imshsi2c_main_4.vbusp region 0 firewall.
  fields as CBASS_FW_IADC12FC_16FFC_MAIN_0_CBA0_CFG_FW_REGION_0_END_ADDRESS_L
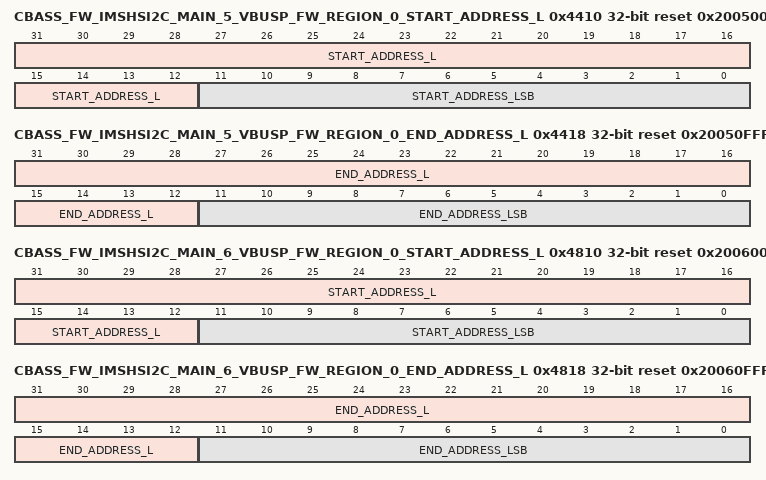
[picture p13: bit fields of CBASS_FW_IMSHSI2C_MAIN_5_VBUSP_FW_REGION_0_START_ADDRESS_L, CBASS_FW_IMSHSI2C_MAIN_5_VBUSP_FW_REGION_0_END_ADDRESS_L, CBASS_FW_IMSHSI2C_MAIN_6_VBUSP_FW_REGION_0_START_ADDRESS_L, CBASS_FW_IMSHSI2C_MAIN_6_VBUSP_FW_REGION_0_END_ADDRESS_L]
0x4410 CBASS_FW_IMSHSI2C_MAIN_5_VBUSP_FW_REGION_0_START_ADDRESS_L access per field reset 0x20050000 — The FW Region 0 Start Address Low Register defines the start address bits 31 to 0 for the target Imshsi2c_main_5.vbusp region 0 firewall.
  fields as CBASS_FW_IADC12FC_16FFC_MAIN_0_CBA0_CFG_FW_REGION_0_START_ADDRESS_L
0x4418 CBASS_FW_IMSHSI2C_MAIN_5_VBUSP_FW_REGION_0_END_ADDRESS_L access per field reset 0x20050FFF — The FW Region 0 End Address Low Register defines the end address bits 31 to 0 to include for the target Imshsi2c_main_5.vbusp region 0 firewall.
  fields as CBASS_FW_IADC12FC_16FFC_MAIN_0_CBA0_CFG_FW_REGION_0_END_ADDRESS_L
0x4810 CBASS_FW_IMSHSI2C_MAIN_6_VBUSP_FW_REGION_0_START_ADDRESS_L access per field reset 0x20060000 — The FW Region 0 Start Address Low Register defines the start address bits 31 to 0 for the target Imshsi2c_main_6.vbusp region 0 firewall.
  fields as CBASS_FW_IADC12FC_16FFC_MAIN_0_CBA0_CFG_FW_REGION_0_START_ADDRESS_L
0x4818 CBASS_FW_IMSHSI2C_MAIN_6_VBUSP_FW_REGION_0_END_ADDRESS_L access per field reset 0x20060FFF — The FW Region 0 End Address Low Register defines the end address bits 31 to 0 to include for the target Imshsi2c_main_6.vbusp region 0 firewall.
  fields as CBASS_FW_IADC12FC_16FFC_MAIN_0_CBA0_CFG_FW_REGION_0_END_ADDRESS_L
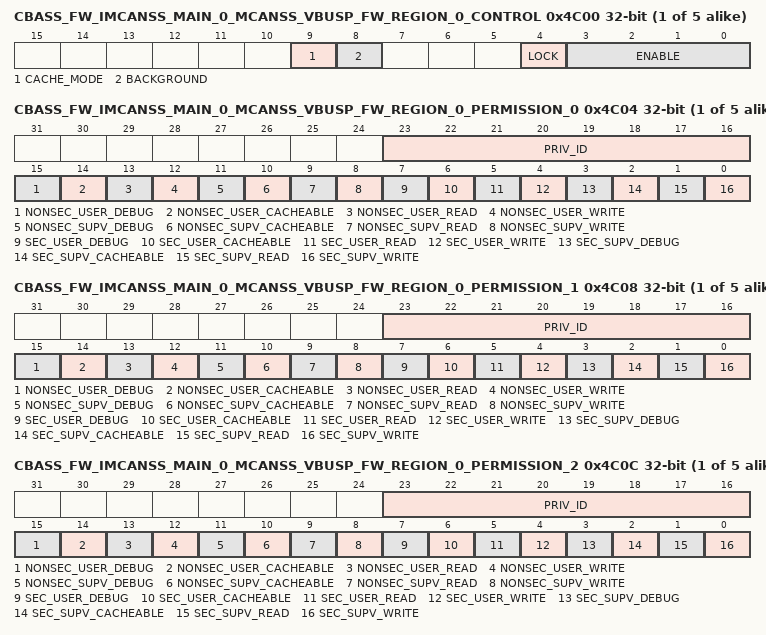
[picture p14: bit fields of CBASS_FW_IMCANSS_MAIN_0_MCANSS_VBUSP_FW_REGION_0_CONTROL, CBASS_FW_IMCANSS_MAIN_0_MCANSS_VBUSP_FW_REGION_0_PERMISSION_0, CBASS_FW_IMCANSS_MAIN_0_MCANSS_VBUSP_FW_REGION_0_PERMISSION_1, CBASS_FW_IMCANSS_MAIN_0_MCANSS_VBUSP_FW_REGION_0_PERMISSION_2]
{0x4C00+0x400*i} CBASS_FW_IMCANSS_MAIN_{i}_MCANSS_VBUSP_FW_REGION_0_CONTROL access not given (i=0..4) — The FW Region 0 Control Register defines the control fields for the target Imcanss_main_{i}.mcanss_vbusp region 0 firewall.
  fields as CBASS_FW_IADC12FC_16FFC_MAIN_0_CBA0_CFG_FW_REGION_0_CONTROL
{0x4C04+0x400*i} CBASS_FW_IMCANSS_MAIN_{i}_MCANSS_VBUSP_FW_REGION_0_PERMISSION_0 (i=0..4) — The FW Region 0 Permission 0 Register defines the permissions for the target Imcanss_main_{i}.mcanss_vbusp region 0 firewall.
  fields as CBASS_FW_IADC12FC_16FFC_MAIN_0_CBA0_CFG_FW_REGION_0_PERMISSION_0
{0x4C08+0x400*i} CBASS_FW_IMCANSS_MAIN_{i}_MCANSS_VBUSP_FW_REGION_0_PERMISSION_1 (i=0..4) — The FW Region 0 Permission 1 Register defines the permissions for the target Imcanss_main_{i}.mcanss_vbusp region 0 firewall.
  fields as CBASS_FW_IADC12FC_16FFC_MAIN_0_CBA0_CFG_FW_REGION_0_PERMISSION_0
{0x4C0C+0x400*i} CBASS_FW_IMCANSS_MAIN_{i}_MCANSS_VBUSP_FW_REGION_0_PERMISSION_2 (i=0..4) — The FW Region 0 Permission 2 Register defines the permissions for the target Imcanss_main_{i}.mcanss_vbusp region 0 firewall.
  fields as CBASS_FW_IADC12FC_16FFC_MAIN_0_CBA0_CFG_FW_REGION_0_PERMISSION_0
0x4C10 CBASS_FW_IMCANSS_MAIN_0_MCANSS_VBUSP_FW_REGION_0_START_ADDRESS_L access per field reset 0x20700000 — The FW Region 0 Start Address Low Register defines the start address bits 31 to 0 for the target Imcanss_main_0.mcanss_vbusp region 0 firewall.
  fields as CBASS_FW_IADC12FC_16FFC_MAIN_0_CBA0_CFG_FW_REGION_0_START_ADDRESS_L
{0x4C14+0x400*i} CBASS_FW_IMCANSS_MAIN_{i}_MCANSS_VBUSP_FW_REGION_0_START_ADDRESS_H (i=0..4) — The FW Region 0 Start Address High Register defines the start address bits 47 to 32 for the target Imcanss_main_{i}.mcanss_vbusp region 0 firewall.
  fields as CBASS_FW_IADC12FC_16FFC_MAIN_0_CBA0_CFG_FW_REGION_0_START_ADDRESS_H
0x4C18 CBASS_FW_IMCANSS_MAIN_0_MCANSS_VBUSP_FW_REGION_0_END_ADDRESS_L access per field reset 0x20700FFF — The FW Region 0 End Address Low Register defines the end address bits 31 to 0 to include for the target Imcanss_main_0.mcanss_vbusp region 0 firewall.
  fields as CBASS_FW_IADC12FC_16FFC_MAIN_0_CBA0_CFG_FW_REGION_0_END_ADDRESS_L
{0x4C1C+0x400*i} CBASS_FW_IMCANSS_MAIN_{i}_MCANSS_VBUSP_FW_REGION_0_END_ADDRESS_H (i=0..4) — The FW Region 0 End Address High Register defines the end address bits 47 to 32 to include for the target Imcanss_main_{i}.mcanss_vbusp region 0 firewall.
  fields as CBASS_FW_IADC12FC_16FFC_MAIN_0_CBA0_CFG_FW_REGION_0_END_ADDRESS_H
0x5010 CBASS_FW_IMCANSS_MAIN_1_MCANSS_VBUSP_FW_REGION_0_START_ADDRESS_L access per field reset 0x20710000 — The FW Region 0 Start Address Low Register defines the start address bits 31 to 0 for the target Imcanss_main_1.mcanss_vbusp region 0 firewall.
  fields as CBASS_FW_IADC12FC_16FFC_MAIN_0_CBA0_CFG_FW_REGION_0_START_ADDRESS_L
0x5018 CBASS_FW_IMCANSS_MAIN_1_MCANSS_VBUSP_FW_REGION_0_END_ADDRESS_L access per field reset 0x20710FFF — The FW Region 0 End Address Low Register defines the end address bits 31 to 0 to include for the target Imcanss_main_1.mcanss_vbusp region 0 firewall.
  fields as CBASS_FW_IADC12FC_16FFC_MAIN_0_CBA0_CFG_FW_REGION_0_END_ADDRESS_L
0x5410 CBASS_FW_IMCANSS_MAIN_2_MCANSS_VBUSP_FW_REGION_0_START_ADDRESS_L access per field reset 0x20720000 — The FW Region 0 Start Address Low Register defines the start address bits 31 to 0 for the target Imcanss_main_2.mcanss_vbusp region 0 firewall.
  fields as CBASS_FW_IADC12FC_16FFC_MAIN_0_CBA0_CFG_FW_REGION_0_START_ADDRESS_L
0x5418 CBASS_FW_IMCANSS_MAIN_2_MCANSS_VBUSP_FW_REGION_0_END_ADDRESS_L access per field reset 0x20720FFF — The FW Region 0 End Address Low Register defines the end address bits 31 to 0 to include for the target Imcanss_main_2.mcanss_vbusp region 0 firewall.
  fields as CBASS_FW_IADC12FC_16FFC_MAIN_0_CBA0_CFG_FW_REGION_0_END_ADDRESS_L
0x5810 CBASS_FW_IMCANSS_MAIN_3_MCANSS_VBUSP_FW_REGION_0_START_ADDRESS_L access per field reset 0x20730000 — The FW Region 0 Start Address Low Register defines the start address bits 31 to 0 for the target Imcanss_main_3.mcanss_vbusp region 0 firewall.
  fields as CBASS_FW_IADC12FC_16FFC_MAIN_0_CBA0_CFG_FW_REGION_0_START_ADDRESS_L
0x5818 CBASS_FW_IMCANSS_MAIN_3_MCANSS_VBUSP_FW_REGION_0_END_ADDRESS_L access per field reset 0x20730FFF — The FW Region 0 End Address Low Register defines the end address bits 31 to 0 to include for the target Imcanss_main_3.mcanss_vbusp region 0 firewall.
  fields as CBASS_FW_IADC12FC_16FFC_MAIN_0_CBA0_CFG_FW_REGION_0_END_ADDRESS_L
0x5C10 CBASS_FW_IMCANSS_MAIN_4_MCANSS_VBUSP_FW_REGION_0_START_ADDRESS_L access per field reset 0x20740000 — The FW Region 0 Start Address Low Register defines the start address bits 31 to 0 for the target Imcanss_main_4.mcanss_vbusp region 0 firewall.
  fields as CBASS_FW_IADC12FC_16FFC_MAIN_0_CBA0_CFG_FW_REGION_0_START_ADDRESS_L
0x5C18 CBASS_FW_IMCANSS_MAIN_4_MCANSS_VBUSP_FW_REGION_0_END_ADDRESS_L access per field reset 0x20740FFF — The FW Region 0 End Address Low Register defines the end address bits 31 to 0 to include for the target Imcanss_main_4.mcanss_vbusp region 0 firewall.
  fields as CBASS_FW_IADC12FC_16FFC_MAIN_0_CBA0_CFG_FW_REGION_0_END_ADDRESS_L
0x6000 CBASS_FW_ISAM67_PDMA_SPI_MAIN_0_ECCAGGR_CFG_FW_REGION_0_CONTROL access not given — The FW Region 0 Control Register defines the control fields for the target Isam67_pdma_spi_main_0.eccaggr_cfg region 0 firewall.
  fields as CBASS_FW_IADC12FC_16FFC_MAIN_0_CBA0_CFG_FW_REGION_0_CONTROL
{0x6004+4i} CBASS_FW_ISAM67_PDMA_SPI_MAIN_0_ECCAGGR_CFG_FW_REGION_0_PERMISSION_{i} (i=0..2) — The FW Region 0 Permission {i} Register defines the permissions for the target Isam67_pdma_spi_main_0.eccaggr_cfg region 0 firewall.
  fields as CBASS_FW_IADC12FC_16FFC_MAIN_0_CBA0_CFG_FW_REGION_0_PERMISSION_0
0x6010 CBASS_FW_ISAM67_PDMA_SPI_MAIN_0_ECCAGGR_CFG_FW_REGION_0_START_ADDRESS_L access per field reset 0xC00000 — The FW Region 0 Start Address Low Register defines the start address bits 31 to 0 for the target Isam67_pdma_spi_main_0.eccaggr_cfg region 0 firewall.
  fields as CBASS_FW_IADC12FC_16FFC_MAIN_0_CBA0_CFG_FW_REGION_0_START_ADDRESS_L
0x6014 CBASS_FW_ISAM67_PDMA_SPI_MAIN_0_ECCAGGR_CFG_FW_REGION_0_START_ADDRESS_H — The FW Region 0 Start Address High Register defines the start address bits 47 to 32 for the target Isam67_pdma_spi_main_0.eccaggr_cfg region 0 firewall.
  fields as CBASS_FW_IADC12FC_16FFC_MAIN_0_CBA0_CFG_FW_REGION_0_START_ADDRESS_H
0x6018 CBASS_FW_ISAM67_PDMA_SPI_MAIN_0_ECCAGGR_CFG_FW_REGION_0_END_ADDRESS_L access per field reset 0xC00FFF — The FW Region 0 End Address Low Register defines the end address bits 31 to 0 to include for the target Isam67_pdma_spi_main_0.eccaggr_cfg region 0 firewall.
  fields as CBASS_FW_IADC12FC_16FFC_MAIN_0_CBA0_CFG_FW_REGION_0_END_ADDRESS_L
0x601C CBASS_FW_ISAM67_PDMA_SPI_MAIN_0_ECCAGGR_CFG_FW_REGION_0_END_ADDRESS_H — The FW Region 0 End Address High Register defines the end address bits 47 to 32 to include for the target Isam67_pdma_spi_main_0.eccaggr_cfg region 0 firewall.
  fields as CBASS_FW_IADC12FC_16FFC_MAIN_0_CBA0_CFG_FW_REGION_0_END_ADDRESS_H
0x6400 CBASS_FW_IAM275_PDMA_SPI1_MAIN_0_ECCAGGR_CFG_FW_REGION_0_CONTROL access not given — The FW Region 0 Control Register defines the control fields for the target Iam275_pdma_spi1_main_0.eccaggr_cfg region 0 firewall.
  fields as CBASS_FW_IADC12FC_16FFC_MAIN_0_CBA0_CFG_FW_REGION_0_CONTROL
